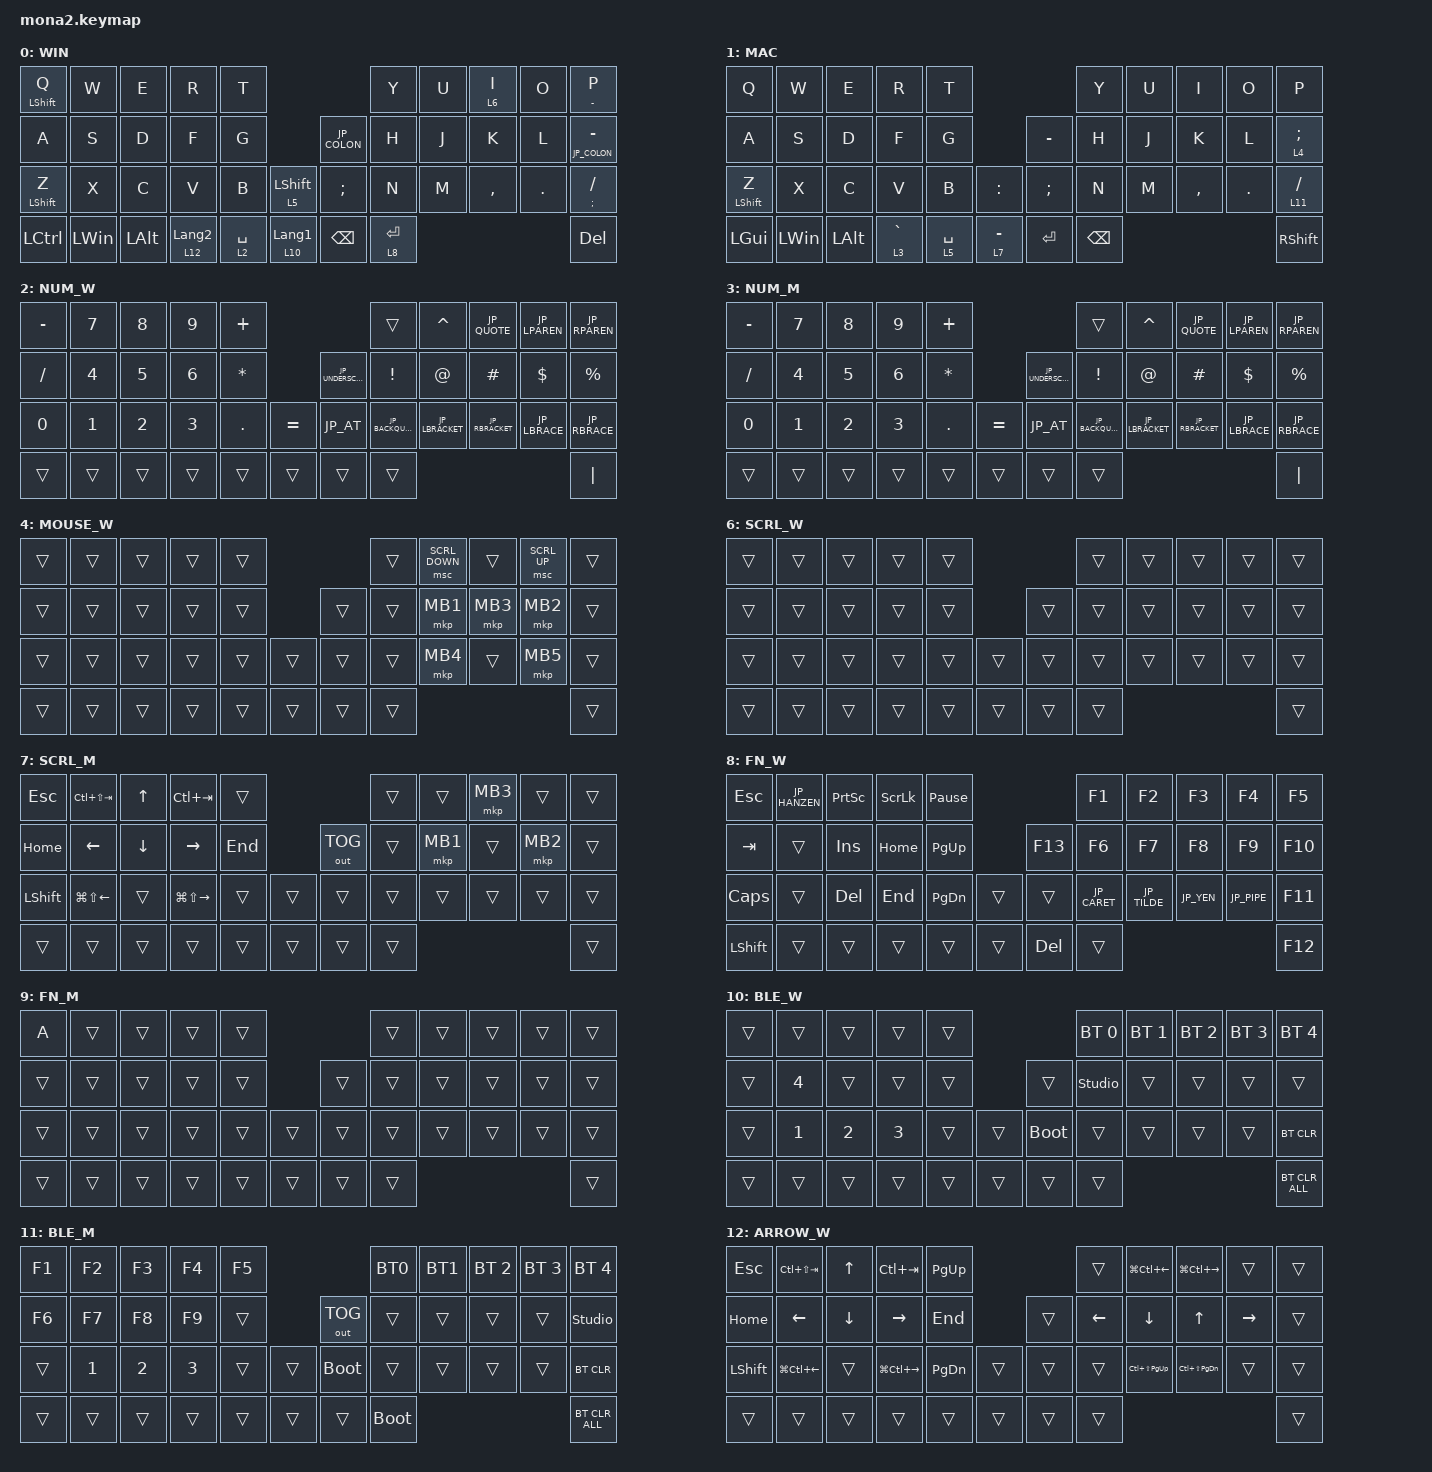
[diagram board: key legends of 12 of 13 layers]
#include <input/processors.dtsi>
#include <dt-bindings/zmk/input_transform.h>
#include <zephyr/dt-bindings/input/input-event-codes.h>
#include <behaviors.dtsi>
#include <behaviors/runtime-sensor-rotate.dtsi>
#include <dt-bindings/zmk/bt.h>
#include <dt-bindings/zmk/keys.h>
#include <dt-bindings/zmk/outputs.h>
#include <dt-bindings/zmk/pointing.h>

/* ZMK 側で 10 が定義済みなので警告回避のため一旦 undef */

#undef ZMK_POINTING_DEFAULT_SCRL_VAL

#define ZMK_POINTING_DEFAULT_SCRL_VAL 100

// OS設定を日本語キーボードのまま使用するための変換定義

#define JP_DQUOTE       AT                // "
#define JP_AMPERSAND    CARET             // &
#define JP_QUOTE        AMPERSAND         // '
#define JP_EQUAL        UNDER             // =
#define JP_CARET        EQUAL             // ^
#define JP_YEN          0x89              // ¥
#define JP_PLUS         COLON             // +
#define JP_TILDE        PLUS              // ~
#define JP_PIPE         LS(0x89)          // |
#define JP_AT           LEFT_BRACKET      // @
#define JP_COLON        SINGLE_QUOTE      // :
#define JP_ASTERISK     DOUBLE_QUOTES     // *
#define JP_BACKQUOTE    LEFT_BRACE        // `
#define JP_UNDERSCORE   LS(0x87)          // _
#define JP_LBRACKET     RIGHT_BRACKET     // [
#define JP_RBRACKET     BACKSLASH         // ]
#define JP_LPAREN       ASTERISK          // (
#define JP_RPAREN       LEFT_PARENTHESIS  // )
#define JP_LBRACE       RIGHT_BRACE       // {
#define JP_RBRACE       PIPE              // }
#define JP_KANA         LANGUAGE_1        // かな
#define JP_EISU         LANGUAGE_2        // 英数
#define JP_HANZEN       GRAVE             // 半角/全角


/ {
    behaviors {
        mg_set_0: behavior_mg_set_0 {
            compatible = "zmk,behavior-mg-set-fixed";
            #binding-cells = <0>;
            display-name = "Mouse Gesture Key 0";
        };

        mg_set_1: behavior_mg_set_1 {
            compatible = "zmk,behavior-mg-set-fixed";
            #binding-cells = <0>;
            display-name = "Mouse Gesture Key 1";
        };

        mg_set_2: behavior_mg_set_2 {
            compatible = "zmk,behavior-mg-set-fixed";
            #binding-cells = <0>;
            display-name = "Mouse Gesture Key 2";
        };
    };
};

&mt {
    flavor = "balanced";
    quick-tap-ms = <0>;
};

&lt {
    quick-tap-ms = <200>;
    flavor = "balanced";
};

&msc {
    delay-ms = <0>;
    time-to-max-speed-ms = <0>;
    acceleration-exponent = <0>;
};

/ {
    /* ─────────────────────────────────────────────────────────────
       コンボ (DYA Studio から編集可能)

       旧 `combos { compatible = "zmk,combos"; }` はコンパイル時固定で
       DYA Studio から編集できないため、zmk-feature-runtime-combo の
       「コンパイル時デフォルト」ノードへ移行した。
       ここに書いた内容はフラッシュ直後から有効で、設定を消しても復活する。
       DYA Studio 側で編集するとそのスロットだけ上書きされ、
       Web UI の "Reset to Default" でここの値へ戻せる。

       スロット総数は CONFIG_ZMK_RUNTIME_COMBO_MAX_COMBOS (現状 16)。
       未使用スロット (2〜15) は DYA Studio から自由に追加できる。
       ────────────────────────────────────────────────────────── */
    runtime_combo_defaults {
        compatible = "cormoran,runtime-combo-defaults";

        layer4_ESC {
            slot = <0>;
            display-name = "Layer4 ESC";
            key-positions = <38 39>;
            bindings = <&lt 4 ESC>;
        };

        tab {
            slot = <1>;
            display-name = "Tab";
            key-positions = <11 12>;
            bindings = <&kp TAB>;
        };

        shift_tab {
          bindings = <&kp LS(TAB)>;
          key-positions = <12 13>;
        };

        double_quotation {
          bindings = <&kp DOUBLE_QUOTES>;
          key-positions = <20 21>;
        };

        eq {
          bindings = <&kp EQUAL>;
          key-positions = <24 25>;
        };

    };

    /* 静的マクロ。キーマップ上で &BT0 / &screenshot などの名前で直接
       参照しているため、そのまま残している (DYA Studio 上では編集不可)。
       DYA Studio から編集したいマクロは Web UI で新規作成し、
       キーに `&rmacro <slot>` を割り当てて使う。 */
    macros {
        to_layer_0: to_layer_0 {
            compatible = "zmk,behavior-macro-one-param";
            #binding-cells = <1>;
            bindings = <&to 0 &macro_param_1to1 &kp MACRO_PLACEHOLDER>;
            label = "TO_LAYER_0";
        };

        BT0: BT0 {
            compatible = "zmk,behavior-macro";
            #binding-cells = <0>;
            bindings =
                <&tog_off 0 &tog_off 1>,
                <&macro_wait_time 200>,
                <&bt BT_SEL 0>,
                <&macro_wait_time 500>,
                <&tog_on 0>;

            label = "BT0";
        };

        BT1: BT1 {
            compatible = "zmk,behavior-macro";
            #binding-cells = <0>;
            bindings =
                <&tog_off 0 &tog_off 1>,
                <&macro_wait_time 200>,
                <&bt BT_SEL 1>,
                <&macro_wait_time 500>,
                <&tog_on 1>;

            label = "BT1";
        };

        screenshot: screenshot {
            compatible = "zmk,behavior-macro";
            #binding-cells = <0>;
            bindings =
                <&macro_press>,
                <&kp LEFT_GUI &kp RSHIFT>,
                <&macro_wait_time 20>,
                <&macro_tap>,
                <&kp S>,
                <&macro_release>,
                <&kp LEFT_GUI &kp RSHIFT>;

            label = "SCREENSHOT";
        };

        henkan: henkan {
            compatible = "zmk,behavior-macro";
            #binding-cells = <0>;
            bindings =
                <&macro_press>,
                <&kp LEFT_ALT>,
                <&macro_wait_time 20>,
                <&macro_tap>,
                <&kp GRAVE>,
                <&macro_release>,
                <&kp LEFT_ALT>;

            label = "HENKAN";
        };
    };

    behaviors {
        lt_to_layer_0: lt_to_layer_0 {
            compatible = "zmk,behavior-hold-tap";
            label = "LAYER_TAP_TO_0";
            bindings = <&mo>, <&to_layer_0>;

            #binding-cells = <2>;
            tapping-term-ms = <200>;
        };

        tp_repeat_mo1: tp_repeat_mo1 {
            compatible = "zmk,behavior-hold-tap";
            label = "TP_REPEAT_MO1";
            bindings = <&mo>, <&key_repeat>;

            #binding-cells = <2>;
            tapping-term-ms = <200>;
        };

        // エンコーダ用 runtime-configurable sensor rotate
        // デフォルトはスクロール (cw=SCRL_DOWN, ccw=SCRL_UP)
        // DYA Studio Web UI から レイヤーごとに cw/ccw の binding を
        // kp C_VOL_UP/DN や kp LEFT/RIGHT などへ動的変更可能

        rsr_default: rsr_default {
            compatible = "zmk,behavior-runtime-sensor-rotate";
            #sensor-binding-cells = <0>;
            tap-ms = <16>;
            cw-binding = <&msc SCRL_DOWN>;
            ccw-binding = <&msc SCRL_UP>;
        };

        tog_on: toggle_layer_on_only {
            compatible = "zmk,behavior-toggle-layer";
            #binding-cells = <1>;
            display-name = "Toggle Layer On";
            toggle-mode = "on";
        };

        tog_off: toggle_layer_off_only {
            compatible = "zmk,behavior-toggle-layer";
            #binding-cells = <1>;
            display-name = "Toggle Layer Off";
            toggle-mode = "off";
        };

        zfold: zfold {
            compatible = "zmk,behavior-hold-tap";
            label = "ZFOLD";
            bindings = <&kp>, <&kp>;

            #binding-cells = <2>;
            tapping-term-ms = <300>;
            flavor = "hold-preferred";
            quick-tap-ms = <150>;
            hold-while-undecided;
        };

        zfoldZ: zfoldZ {
            compatible = "zmk,behavior-tap-dance";
            label = "ZFOLDZ";
            #binding-cells = <0>;
            bindings = <&zfold LEFT_SHIFT Z>, <&kp LS(Z)>;
        };
    };

    keymap {
        compatible = "zmk,keymap";

        win_layer {
            display-name = "WIN";
            bindings = <
&mt LEFT_SHIFT Q  &kp W         &kp E         &kp R              &kp T                                           &kp Y        &kp U  &lt 6 I   &kp O    &mt MINUS P
&kp A             &kp S         &kp D         &kp F              &kp G                            &kp JP_COLON   &kp H        &kp J  &kp K     &kp L    &mt JP_COLON MINUS
&mt LEFT_SHIFT Z  &kp X         &kp C         &kp V              &kp B        &lt 5 LEFT_SHIFT    &kp SEMICOLON  &kp N        &kp M  &kp COMMA &kp DOT  &mt SEMICOLON SLASH
&kp LCTRL         &kp LEFT_WIN  &kp LEFT_ALT  &lt 12 LANGUAGE_2  &lt 2 SPACE  &lt 10 LANGUAGE_1   &kp BACKSPACE  &lt 8 ENTER                            &kp DEL
            >;

            sensor-bindings = <&rsr_default>, <&inc_dec_kp C_VOL_DN C_VOL_UP>;
        };

        mac_layer {
            display-name = "MAC";
            bindings = <
&kp Q             &kp W         &kp E         &kp R        &kp T                                      &kp Y          &kp U  &kp I      &kp O    &kp P
&kp A             &kp S         &kp D         &kp F        &kp G                       &kp MINUS      &kp H          &kp J  &kp K      &kp L    &lt 4 SEMICOLON
&mt LEFT_SHIFT Z  &kp X         &kp C         &kp V        &kp B        &kp COLON      &kp SEMICOLON  &kp N          &kp M  &kp COMMA  &kp DOT  &lt 11 SLASH
&kp LEFT_GUI      &kp LEFT_WIN  &kp LEFT_ALT  &lt 3 GRAVE  &lt 5 SPACE  &lt 7 MINUS    &kp ENTER      &kp BACKSPACE                             &kp RIGHT_SHIFT
            >;

            sensor-bindings = <&rsr_default>, <&inc_dec_kp C_VOL_DN C_VOL_UP>;
        };

        num_win {
            display-name = "NUM_W";
            bindings = <
&kp MINUS     &kp NUMBER_7  &kp NUMBER_8  &kp NUMBER_9  &kp PLUS                                                      &trans            &kp CARET        &kp JP_QUOTE     &kp JP_LPAREN  &kp JP_RPAREN
&kp SLASH     &kp NUMBER_4  &kp NUMBER_5  &kp NUMBER_6  &kp ASTERISK                               &kp JP_UNDERSCORE  &kp EXCLAMATION   &kp AT_SIGN      &kp HASH         &kp DOLLAR     &kp PERCENT
&kp NUMBER_0  &kp NUMBER_1  &kp NUMBER_2  &kp NUMBER_3  &kp PERIOD    &kp EQUAL                    &kp JP_AT          &kp JP_BACKQUOTE  &kp JP_LBRACKET  &kp JP_RBRACKET  &kp JP_LBRACE  &kp JP_RBRACE
&trans        &trans        &trans        &trans        &trans        &trans                       &trans             &trans                                                             &kp PIPE
            >;

            sensor-bindings = <&rsr_default>;
        };

        num_mac {
            display-name = "NUM_M";
            bindings = <
&kp MINUS     &kp NUMBER_7  &kp NUMBER_8  &kp NUMBER_9  &kp PLUS                                                      &trans            &kp CARET        &kp JP_QUOTE     &kp JP_LPAREN  &kp JP_RPAREN
&kp SLASH     &kp NUMBER_4  &kp NUMBER_5  &kp NUMBER_6  &kp ASTERISK                               &kp JP_UNDERSCORE  &kp EXCLAMATION   &kp AT_SIGN      &kp HASH         &kp DOLLAR     &kp PERCENT
&kp NUMBER_0  &kp NUMBER_1  &kp NUMBER_2  &kp NUMBER_3  &kp PERIOD    &kp EQUAL                    &kp JP_AT          &kp JP_BACKQUOTE  &kp JP_LBRACKET  &kp JP_RBRACKET  &kp JP_LBRACE  &kp JP_RBRACE
&trans        &trans        &trans        &trans        &trans        &trans                       &trans             &trans                                                             &kp PIPE
            >;

            sensor-bindings = <&rsr_default>;
        };

        mouse_win {
            display-name = "MOUSE_W";
            bindings = <
&trans  &trans  &trans  &trans  &trans                      &trans  &msc SCRL_DOWN  &trans    &msc SCRL_UP  &trans
&trans  &trans  &trans  &trans  &trans              &trans  &trans  &mkp MB1        &mkp MB3  &mkp MB2      &trans
&trans  &trans  &trans  &trans  &trans  &trans      &trans  &trans  &mkp MB4        &trans    &mkp MB5      &trans
&trans  &trans  &trans  &trans  &trans  &trans      &trans  &trans                                          &trans
            >;

            sensor-bindings = <&rsr_default>;
        };

        mouse_mac {
            display-name = "MOUSE_M";
            bindings = <
&kp ESCAPE                  &kp LG(Z)       &kp UP_ARROW              &kp LG(LS(Z))    &kp LG(V)                                  &kp CARET         &kp AMPERSAND      &mkp MB3        &kp LEFT_PARENTHESIS  &kp RIGHT_PARENTHESIS
&kp TAB                     &kp LEFT_ARROW  &kp LG(LC(LS(NUMBER_4)))  &kp RIGHT_ARROW  &kp LG(A)                  &kp UNDERSCORE  &kp EXCLAMATION   &mkp MB1           &mo 7           &mkp MB2              &kp LC(SPACE)
&mt LEFT_SHIFT KP_NUMBER_0  &kp LG(LC(Z))   &kp DOWN_ARROW            &kp LG(RIGHT)    &kp LG(LEFT)  &kp EQUAL    &trans          &kp LEFT_BRACKET  &kp RIGHT_BRACKET  &kp LEFT_BRACE  &kp RIGHT_BRACE       &kp LC(SPACE)
&kp LCTRL                   &trans          &trans                    &trans           &trans        &trans       &kp ENTER       &kp BACKSPACE                                                              &kp PIPE
            >;

            sensor-bindings = <&rsr_default>;
        };

        scroll_win {
            display-name = "SCRL_W";
            bindings = <
&trans  &trans  &trans  &trans  &trans                      &trans  &trans  &trans  &trans  &trans
&trans  &trans  &trans  &trans  &trans              &trans  &trans  &trans  &trans  &trans  &trans
&trans  &trans  &trans  &trans  &trans  &trans      &trans  &trans  &trans  &trans  &trans  &trans
&trans  &trans  &trans  &trans  &trans  &trans      &trans  &trans                          &trans
            >;

            sensor-bindings = <&rsr_default>;
        };

        scroll_mac {
            display-name = "SCRL_M";
            bindings = <
&kp ESCAPE      &kp LC(LS(TAB))         &kp UP_ARROW    &kp LC(TAB)              &trans                           &trans  &trans    &mkp MB3  &trans    &trans
&kp HOME        &kp LEFT_ARROW          &kp DOWN_ARROW  &kp RIGHT_ARROW          &kp END            &out OUT_TOG  &trans  &mkp MB1  &trans    &mkp MB2  &trans
&kp LEFT_SHIFT  &kp LG(LS(LEFT_ARROW))  &trans          &kp LG(LS(RIGHT_ARROW))  &trans   &trans    &trans        &trans  &trans    &trans    &trans    &trans
&trans          &trans                  &trans          &trans                   &trans   &trans    &trans        &trans                                &trans
            >;

            sensor-bindings = <&rsr_default>;
        };

        function_win {
            display-name = "FN_W";
            bindings = <
&kp ESCAPE      &kp JP_HANZEN  &kp PRINTSCREEN  &kp SCROLLLOCK  &kp PAUSE_BREAK                       &kp F1        &kp F2        &kp F3      &kp F4       &kp F5
&kp TAB         &trans         &kp INSERT       &kp HOME        &kp PAGE_UP                  &kp F13  &kp F6        &kp F7        &kp F8      &kp F9       &kp F10
&kp CAPS        &trans         &kp DELETE       &kp END         &kp PAGE_DOWN    &trans      &trans   &kp JP_CARET  &kp JP_TILDE  &kp JP_YEN  &kp JP_PIPE  &kp F11
&kp LEFT_SHIFT  &trans         &trans           &trans          &trans           &trans      &kp DEL  &trans                                               &kp F12
            >;
        };

        function_mac {
            display-name = "FN_M";
            bindings = <
&kp A   &trans  &trans  &trans  &trans                    &trans  &trans  &trans  &trans  &trans
&trans  &trans  &trans  &trans  &trans            &trans  &trans  &trans  &trans  &trans  &trans
&trans  &trans  &trans  &trans  &trans  &trans    &trans  &trans  &trans  &trans  &trans  &trans
&trans  &trans  &trans  &trans  &trans  &trans    &trans  &trans                          &trans
            >;
        };

        ble_win {
            display-name = "BLE_W";
            bindings = <
&trans  &trans        &trans        &trans        &trans                           &bt BT_SEL 0  &bt BT_SEL 1  &bt BT_SEL 2  &bt BT_SEL 3  &bt BT_SEL 4
&trans  &kp NUMBER_4  &trans        &trans        &trans              &trans       &studio_unlock &trans        &trans        &trans        &trans
&trans  &kp NUMBER_1  &kp NUMBER_2  &kp NUMBER_3  &trans  &trans      &bootloader  &trans        &trans        &trans        &trans        &bt BT_CLR
&trans  &trans        &trans        &trans        &trans  &trans      &trans       &trans                                                  &bt BT_CLR_ALL
            >;
        };

        ble_mac {
            display-name = "BLE_M";
            bindings = <
&kp F1  &kp F2        &kp F3        &kp F4        &kp F5                          &BT0         &BT1    &bt BT_SEL 2  &bt BT_SEL 3  &bt BT_SEL 4
&kp F6  &kp F7        &kp F8        &kp F9        &trans            &out OUT_TOG  &trans       &trans  &trans        &trans        &studio_unlock
&trans  &kp NUMBER_1  &kp NUMBER_2  &kp NUMBER_3  &trans  &trans    &bootloader   &trans       &trans  &trans        &trans        &bt BT_CLR
&trans  &trans        &trans        &trans        &trans  &trans    &trans        &bootloader                                      &bt BT_CLR_ALL
            >;
        };

        arrow_win{
          display-name = "ARROW_W";
          bindings = <
&kp ESCAPE      &kp LC(LS(TAB))         &kp UP_ARROW    &kp LC(TAB)              &kp PAGE_UP                        &trans          &kp LG(LC(LEFT_ARROW))  &kp LG(LC(RIGHT_ARROW))  &trans           &trans
&kp HOME        &kp LEFT_ARROW          &kp DOWN_ARROW  &kp RIGHT_ARROW          &kp END                    &trans  &kp LEFT_ARROW  &kp DOWN_ARROW          &kp UP_ARROW             &kp RIGHT_ARROW  &trans
&kp LEFT_SHIFT  &kp LG(LC(LEFT_ARROW))  &trans          &kp LG(LC(RIGHT_ARROW))  &kp PAGE_DOWN  &trans      &trans  &trans          &kp LC(LS(PG_UP))       &kp LC(LS(PG_DN))        &trans           &trans
&trans          &trans                  &trans          &trans                   &trans         &trans      &trans  &trans                                                                            &trans
            >;
        };
    };
};
